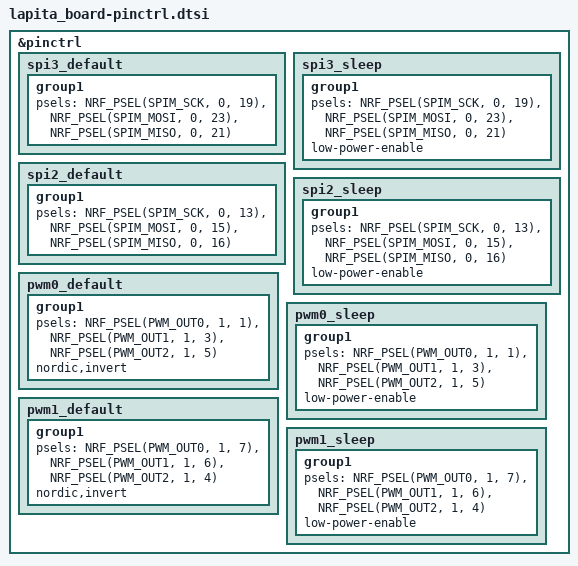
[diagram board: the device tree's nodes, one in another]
// Copyright (c) 2023 Nordic Semiconductor ASA
// SPDX-License-Identifier: Apache-2.0

&pinctrl {
	spi3_default: spi3_default {
		group1 {
			psels = <NRF_PSEL(SPIM_SCK, 0, 19)>,
			        <NRF_PSEL(SPIM_MOSI, 0, 23)>,
			        <NRF_PSEL(SPIM_MISO, 0, 21)>;
		};
	};

	spi3_sleep: spi3_sleep {
		group1 {
			psels = <NRF_PSEL(SPIM_SCK, 0, 19)>,
			        <NRF_PSEL(SPIM_MOSI, 0, 23)>,
			        <NRF_PSEL(SPIM_MISO, 0, 21)>;
			low-power-enable;
		};
	};

	spi2_default: spi2_default {
		group1 {
			psels = <NRF_PSEL(SPIM_SCK, 0, 13)>,
			        <NRF_PSEL(SPIM_MOSI, 0, 15)>,
			        <NRF_PSEL(SPIM_MISO, 0, 16)>;
		};
	};

	spi2_sleep: spi2_sleep {
		group1 {
			psels = <NRF_PSEL(SPIM_SCK, 0, 13)>,
			        <NRF_PSEL(SPIM_MOSI, 0, 15)>,
			        <NRF_PSEL(SPIM_MISO, 0, 16)>;
			low-power-enable;
		};
	};

	pwm0_default: pwm0_default {
		group1 {
			psels = <NRF_PSEL(PWM_OUT0, 1, 1)>,
			        <NRF_PSEL(PWM_OUT1, 1, 3)>,
			        <NRF_PSEL(PWM_OUT2, 1, 5)>;
			nordic,invert;
		};
	};

	pwm0_sleep: pwm0_sleep {
		group1 {
			psels = <NRF_PSEL(PWM_OUT0, 1, 1)>,
			        <NRF_PSEL(PWM_OUT1, 1, 3)>,
			        <NRF_PSEL(PWM_OUT2, 1, 5)>;
			low-power-enable;
		};
	};

	pwm1_default: pwm1_default {
		group1 {
			psels = <NRF_PSEL(PWM_OUT0, 1, 7)>,
			        <NRF_PSEL(PWM_OUT1, 1, 6)>,
			        <NRF_PSEL(PWM_OUT2, 1, 4)>;
			nordic,invert;
		};
	};

	pwm1_sleep: pwm1_sleep {
		group1 {
			psels = <NRF_PSEL(PWM_OUT0, 1, 7)>,
			        <NRF_PSEL(PWM_OUT1, 1, 6)>,
			        <NRF_PSEL(PWM_OUT2, 1, 4)>;
			low-power-enable;
		};
	};
};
